# TREMO register map
File version: 1.6.2
CPU: CM4 r0p1, little endian, MPU, FPU, 3 interrupt priority bits
Registers are 32-bit, read-write, reset 0x0 unless marked. A register's access mark holds for its fields unless they carry their own. Offsets are from the block's base; [hi:lo] are bit positions; lines under a group give offsets from that group; {n}, {i} and the like mark numbered series.

## SEC
Base 0x4000F000
0x00 INT reset 0x1 — interrupt enable register
  [0] ADDRFAULTEN — Invalid Address Bus Fault Response Enable
0x04 RST reset 0x1 — reset enable register
  [0] ADDRFAULTEN — Invalid Address Bus Fault Response Enable
0x0C SR reset 0x1 — status
  [0] ADDRFAULTEN — Invalid Address Bus Fault Response Enable
0x10 FILTER0 reset 0x1
  [0] ADDRFAULTEN — Invalid Address Bus Fault Response Enable
0x14 FILTER1 reset 0x1
  [0] ADDRFAULTEN — Invalid Address Bus Fault Response Enable
0x24 FILTER2 reset 0x1
  [0] ADDRFAULTEN — Invalid Address Bus Fault Response Enable
0x28 FILTER3 reset 0x1
  [0] ADDRFAULTEN — Invalid Address Bus Fault Response Enable

## QSPI
Base 0x40021000
0x00 QSPI_CR — control register
  [0] ADDRFAULTEN — Invalid Address Bus Fault Response Enable
0x04 QSPI_DCR reset 0x1 — device configuration register
  [0] ADDRFAULTEN — Invalid Address Bus Fault Response Enable
0x08 QSPI_SR reset 0x1 — status register
  [0] ADDRFAULTEN — Invalid Address Bus Fault Response Enable
0x0C QSPI_FCR reset 0x1 — flag clear register
  [0] ADDRFAULTEN — Invalid Address Bus Fault Response Enable
0x10 QSPI_DLR reset 0x1 — data length register
  [0] ADDRFAULTEN — Invalid Address Bus Fault Response Enable
0x14 QSPI_CCR reset 0x1 — communication configuration register
  [0] ADDRFAULTEN — Invalid Address Bus Fault Response Enable
0x18 QSPI_AR reset 0x1 — address register
  [0] ADDRFAULTEN — Invalid Address Bus Fault Response Enable
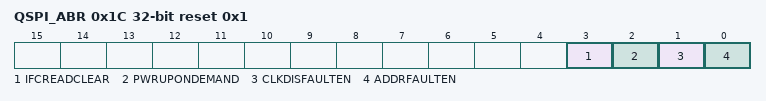
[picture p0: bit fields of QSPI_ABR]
0x1C QSPI_ABR reset 0x1 — alternate byte register
  [3] IFCREADCLEAR — IFC Read Clears IF
  [2] PWRUPONDEMAND — Power Up on Demand During Wake Up
  [1] CLKDISFAULTEN — Clock-disabled Bus Fault Response Enable
  [0] ADDRFAULTEN — Invalid Address Bus Fault Response Enable
0x20 QSPI_DR reset 0x1 — data register
  [0] ADDRFAULTEN — Invalid Address Bus Fault Response Enable
0x24 QSPI_PSMKR reset 0x1 — polling status mask register
  [0] ADDRFAULTEN — Invalid Address Bus Fault Response Enable
0x28 QSPI_PSMAR reset 0x1 — polling status match register
  [0] ADDRFAULTEN — Invalid Address Bus Fault Response Enable
0x2C QSPI_PIR reset 0x1 — polling interval register
  [0] ADDRFAULTEN — Invalid Address Bus Fault Response Enable
0x30 QSPI_TOR reset 0x1 — timeout register
  [0] ADDRFAULTEN — Invalid Address Bus Fault Response Enable
0x80 QSPI_HIT0R reset 0x1 — hit0 times accumulator register
  [0] ADDRFAULTEN — Invalid Address Bus Fault Response Enable
0x84 QSPI_HIT1R reset 0x1 — hit1 times accumulator register
  [0] ADDRFAULTEN — Invalid Address Bus Fault Response Enable
0x88 QSPI_MIR reset 0x1 — miss times accumulator register
  [0] ADDRFAULTEN — Invalid Address Bus Fault Response Enable
0x8C QSPI_CFGR reset 0x1 — configuration register
  [0] ADDRFAULTEN — Invalid Address Bus Fault Response Enable
0x90 SBUS_START reset 0x1 — start register
  [0] ADDRFAULTEN — Invalid Address Bus Fault Response Enable

## DAC
Base 0x40019000
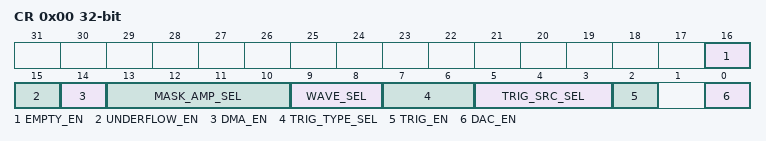
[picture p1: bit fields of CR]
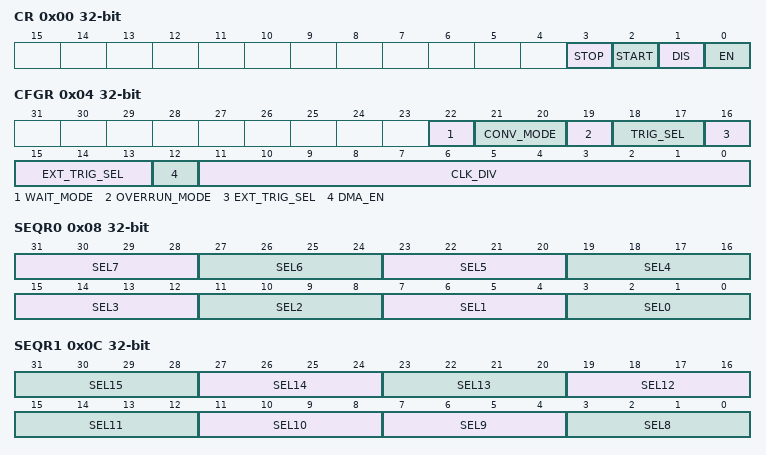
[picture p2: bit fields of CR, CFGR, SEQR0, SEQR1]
0x00 CR — control register
  [16] EMPTY_EN, [15] UNDERFLOW_EN, [14] DMA_EN, [13:10] MASK_AMP_SEL, [9:8] WAVE_SEL, [7:6] TRIG_TYPE_SEL, [5:3] TRIG_SRC_SEL, [2] TRIG_EN, [0] DAC_EN
0x04 SWTRIGR wo — software trigger register
0x08 DHR — data holding register
0x0C DOR ro — data output register
0x10 SR — data length register

## ADC
Base 0x40017000
0x00 CR — control register
  [3] STOP — ADC stop conversion command
  [2] START — ADC start conversion command
  [1] DIS wo — ADC disable
  [0] EN — ADC enable
0x04 CFGR — configuration register
  [22] WAIT_MODE — Wait conversion mode
  [21:20] CONV_MODE — ADC conversion mode selection
  [19] OVERRUN_MODE — Overrun management mode
  [18:17] TRIG_SEL — Trigger mode and polarity selection
  [16:13] EXT_TRIG_SEL — External trigger selection for the start of ADC conversion
  [12] DMA_EN — DMA enable
  [11:0] CLK_DIV — ADCCLK prescale
0x08 SEQR0 — sequence0 register
  [4n+3:4n] SEL{n} (n=3..7) — Select the channel number from 1 to 15 as the {n}th in the conversion sequence
  [11:8] SEL2 — Select the channel number from 1 to 15 as the 2nd in the conversion sequence
  [7:4] SEL1 — Select the channel number from 1 to 15 as the 1st in the conversion sequence
  [3:0] SEL0 — Select the channel number from 1 to 15 as the 0th in the conversion sequence
0x0C SEQR1 — sequence1 register
  [4n-29:4n-32] SEL{n} (n=10..15) — Select the channel number from 1 to 15 as the {n}th in the conversion sequence
  [7:4] SEL9 — Select the channel number from 1 to 15 as the 9st in the conversion sequence
  [3:0] SEL8 — Select the channel number from 1 to 15 as the 8th in the conversion sequence
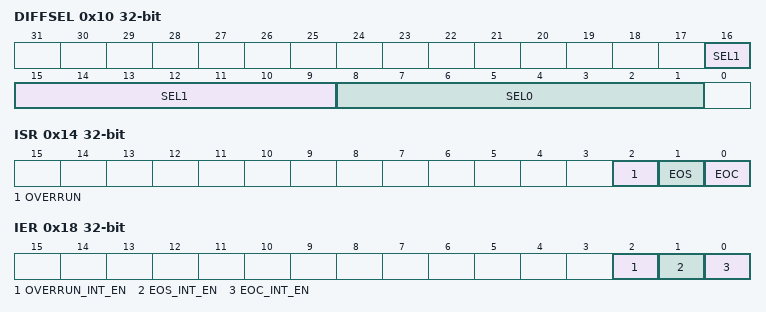
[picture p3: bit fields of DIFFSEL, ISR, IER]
0x10 DIFFSEL — difference register
  [16:9] SEL1 ro — Channels 9 to 15 are internal channels
  [8:1] SEL0 — Differential or single-ended mode selection for Channels 1 to 8
0x14 ISR — interrupt status register
  [2] OVERRUN — ADC conversion overrun flag
  [1] EOS — End of sequence of conversions flag
  [0] EOC — End of conversion flag
0x18 IER — interrupt enable register
  [2] OVERRUN_INT_EN — ADC conversion overrun interrupt enable
  [1] EOS_INT_EN — End of conversion sequence interrupt enable
  [0] EOC_INT_EN — End of conversion interrupt enable
0x1C DR ro — data register
  [11:0] DATA — ADC converted data
{0x20+4i} AWD{i}_CFGR (i=0..2) — AWD{i} register

## BSTIMER0 — Basic timer
Base 0x4000C000
Same registers: BSTIMER1 0x4001C000
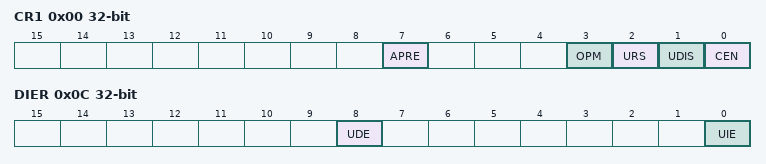
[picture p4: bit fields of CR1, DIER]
0x00 CR1 — control register 1
  [7] APRE — shadow register reload enable
  [3] OPM — One Pulse Mode
  [2] URS — Update Request Source
  [1] UDIS — Update disable
  [0] CEN — Counter enable
0x04 CR2 — control register 2
  [6:4] MMS — Master mode selection
0x0C DIER — DMA/interrupt enable register
  [8] UDE — Update event DMA request enable
  [0] UIE — Update event interrupt request enable
0x10 SR ro — status register
  [0] UIF — Update interrupt flag
0x14 EGR wo — event generation register
  [0] UIF — update event enable
0x24 CNT — TIMER event generation register
  [15:0] CNT — counter register
0x28 PSC reset 0x1 (reset mask 0xF) — prescaler register
  [15:0] PSC — prescaler value
0x2C ARR reset 0x1 (reset mask 0xF) — auto-reload register
  [15:0] ARR — Counter reload value

## SAE — Security subsystem
Base 0x40032000
0x00 SAECR — common control register
  [0] CEN — Counter enable
0x04 SAEHCR — safe control register
  [0] CEN — Counter enable
0x08 SAESR — status register
  [0] CEN — Counter enable
{0xC+4i} SAEGPR{i} (i=0..5) — general group register {i}
  [0] CEN — Counter enable
0x24 SAEMASKCR — mask control register
  [0] CEN — Counter enable
{0x28+4i} SAEMASKDAT{i} (i=0..2) — mask data register {i}
  [0] CEN — Counter enable
0x34 SAEBUFCR — buffer control register
  [0] CEN — Counter enable

## RNG — Random number generator
Base 0x40033000
0x00 RNGDET — control register
  [0] CEN — Counter enable
0x04 RNGSR — status register
  [0] CEN — Counter enable
0x08 RNGCLK — clock register
  [0] CEN — Counter enable
0x0C RNGCR — control register
  [0] CEN — Counter enable
0x10 RNGRESEED — reseed register
  [0] CEN — Counter enable
0x14 RNGDATA — data register
  [0] CEN — Counter enable
0x18 RNGPKNUM
  [0] CEN — Counter enable
{0x1C+4i} RNGPKRES{i} (i=0..2)
  [0] CEN — Counter enable

## NVIC
Base 0xE000E100
{0x0+4i} ISER{i} reset not defined (i=0..7)
  [31:0] ISER
{0x80+4i} ICER{i} reset not defined (i=0..7)
  [31:0] ICER
{0x100+4i} ISPR{i} reset not defined (i=0..7)
  [31:0] ISPR
{0x180+4i} ICPR{i} reset not defined (i=0..7)
  [31:0] ICPR
{0x200+4i} IABR{i} reset not defined (i=0..7)
  [31:0] IABR
